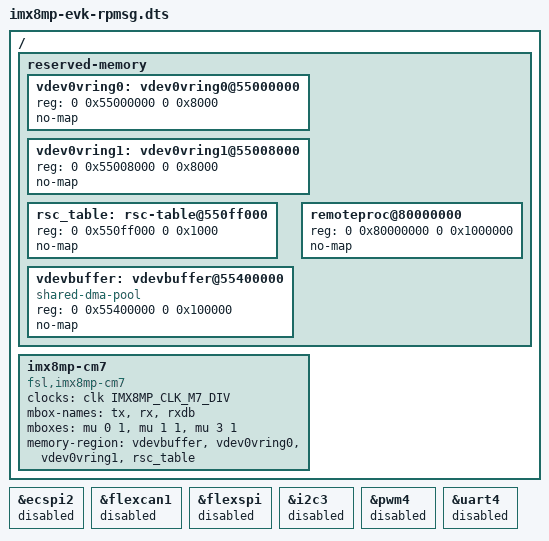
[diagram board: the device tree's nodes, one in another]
// SPDX-License-Identifier: (GPL-2.0 OR MIT)
/*
 * Copyright 2020-2021 NXP
 */

#include "imx8mp-evk.dts"

/ {
	reserved-memory {
		#address-cells = <2>;
		#size-cells = <2>;
		ranges;

		vdev0vring0: vdev0vring0@55000000 {
			reg = <0 0x55000000 0 0x8000>;
			no-map;
		};

		vdev0vring1: vdev0vring1@55008000 {
			reg = <0 0x55008000 0 0x8000>;
			no-map;
		};

		rsc_table: rsc-table@550ff000 {
			reg = <0 0x550ff000 0 0x1000>;
			no-map;
		};

		vdevbuffer: vdevbuffer@55400000 {
			compatible = "shared-dma-pool";
			reg = <0 0x55400000 0 0x100000>;
			no-map;
		};

		remoteproc@80000000 {
			reg = <0 0x80000000 0 0x1000000>;
			no-map;
		};
	};

	imx8mp-cm7 {
		compatible = "fsl,imx8mp-cm7";
		clocks = <&clk IMX8MP_CLK_M7_DIV>;
		mbox-names = "tx", "rx", "rxdb";
		mboxes = <&mu 0 1
			  &mu 1 1
			  &mu 3 1>;
		memory-region = <&vdevbuffer>, <&vdev0vring0>, <&vdev0vring1>,
				<&rsc_table>;
	};
};

/*
 * Below devices are allocated on remoteproc
 */
&ecspi2 {
	status = "disabled";
};

&flexcan1 {
	status = "disabled";
};

&flexspi {
	status = "disabled";
};

&i2c3 {
	status = "disabled";
};

&pwm4 {
	status = "disabled";
};

&uart4 {
	status = "disabled";
};
